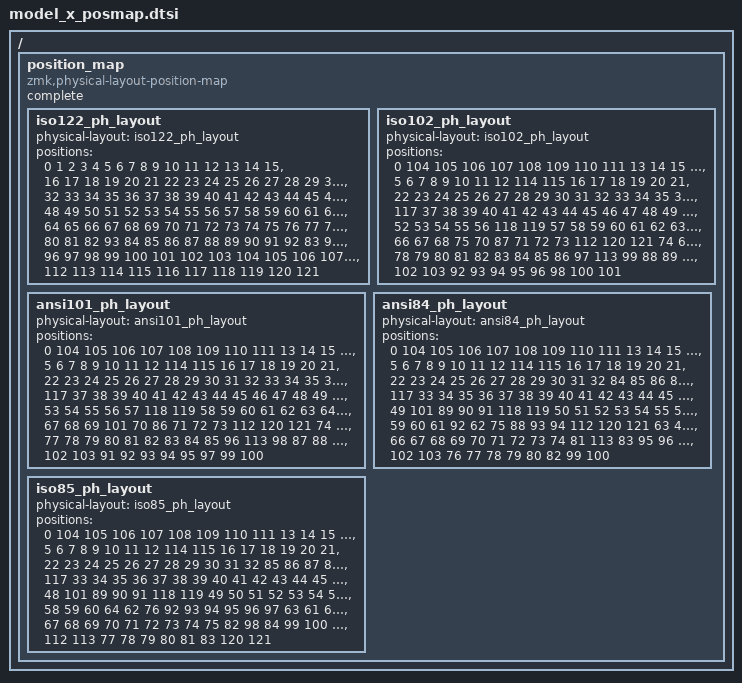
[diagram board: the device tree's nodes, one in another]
// Position mapping made with this tool-> https://zmk-layout-helper.netlify.app/
/ {
    position_map {
        compatible = "zmk,physical-layout-position-map";

        complete;

        iso122_ph_layout {
            physical-layout = <&iso122_ph_layout>;
            positions
                = <  0   1   2   3   4   5   6   7   8   9  10  11  12  13  14  15>
                , < 16  17  18  19  20  21  22  23  24  25  26  27  28  29  30  31>
                , < 32  33  34  35  36  37  38  39  40  41  42  43  44  45  46  47>
                , < 48  49  50  51  52  53  54  55  56  57  58  59  60  61  62  63>
                , < 64  65  66  67  68  69  70  71  72  73  74  75  76  77  78  79>
                , < 80  81  82  93  84  85  86  87  88  89  90  91  92  83  94  95>
                , < 96  97  98  99 100 101 102 103 104 105 106 107 108 109 110 111>
                , <112 113 114 115 116 117 118 119 120 121>
                ;
        };

        iso102_ph_layout {
            physical-layout = <&iso102_ph_layout>;
            positions
                = <  0 104 105 106 107 108 109 110 111  13  14  15   1   2   3   4>
                , <  5   6   7   8   9  10  11  12 114 115  16  17  18  19  20  21>
                , < 22  23  24  25  26  27  28  29  30  31  32  33  34  35  36 116>
                , <117  37  38  39  40  41  42  43  44  45  46  47  48  49  50  51>
                , < 52  53  54  55  56 118 119  57  58  59  60  61  62  63  64  65>
                , < 66  67  68  75  70  87  71  72  73 112 120 121  74  69  76  77>
                , < 78  79  80  81  82  83  84  85  86  97 113  99  88  89  90  91>
                , <102 103  92  93  94  95  96  98 100 101>
                ;
        };

        ansi101_ph_layout {
            physical-layout = <&ansi101_ph_layout>;
            positions
                = <  0 104 105 106 107 108 109 110 111  13  14  15   1   2   3   4>
                , <  5   6   7   8   9  10  11  12 114 115  16  17  18  19  20  21>
                , < 22  23  24  25  26  27  28  29  30  31  32  33  34  35  36 116>
                , <117  37  38  39  40  41  42  43  44  45  46  47  48  49  51  52>
                , < 53  54  55  56  57 118 119  58  59  60  61  62  63  64  65  66>
                , < 67  68  69 101  70  86  71  72  73 112 120 121  74  50  75  76>
                , < 77  78  79  80  81  82  83  84  85  96 113  98  87  88  89  90>
                , <102 103  91  92  93  94  95  97  99 100>
                ;
        };

        ansi84_ph_layout {
            physical-layout = <&ansi84_ph_layout>;
            positions
                = <  0 104 105 106 107 108 109 110 111  13  14  15   1   2   3   4>
                , <  5   6   7   8   9  10  11  12 114 115  16  17  18  19  20  21>
                , < 22  23  24  25  26  27  28  29  30  31  32  84  85  86  87 116>
                , <117  33  34  35  36  37  38  39  40  41  42  43  44  45  47  48>
                , < 49 101  89  90  91 118 119  50  51  52  53  54  55  56  57  58>
                , < 59  60  61  92  62  75  88  93  94 112 120 121  63  46  64  65>
                , < 66  67  68  69  70  71  72  73  74  81 113  83  95  96  97  98>
                , <102 103  76  77  78  79  80  82  99 100>
                ;
        };
        
        iso85_ph_layout {
            physical-layout = <&iso85_ph_layout>;
            positions
                = <  0 104 105 106 107 108 109 110 111  13  14  15   1   2   3   4>
                , <  5   6   7   8   9  10  11  12 114 115  16  17  18  19  20  21>
                , < 22  23  24  25  26  27  28  29  30  31  32  85  86  87  88 116>
                , <117  33  34  35  36  37  38  39  40  41  42  43  44  45  46  47>
                , < 48 101  89  90  91 118 119  49  50  51  52  53  54  55  56  57>
                , < 58  59  60  64  62  76  92  93  94  95  96  97  63  61  65  66>
                , < 67  68  69  70  71  72  73  74  75  82  98  84  99 100 102 103>
                , <112 113  77  78  79  80  81  83 120 121>
                ;
        };
    };
};
